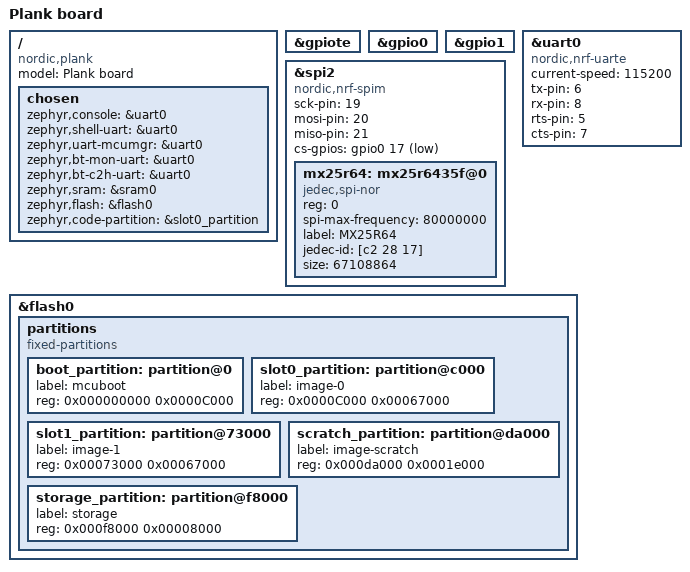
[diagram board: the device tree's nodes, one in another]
/*
 * Copyright (c) 2017 Linaro Limited
 *
 * SPDX-License-Identifier: Apache-2.0
 */

/dts-v1/;
#include <nordic/nrf52840_qiaa.dtsi>

/ {
    model = "Plank board";
    compatible = "nordic,plank";

    chosen {
        zephyr,console = &uart0;
        zephyr,shell-uart = &uart0;
        zephyr,uart-mcumgr = &uart0;
        zephyr,bt-mon-uart = &uart0;
        zephyr,bt-c2h-uart = &uart0;
        zephyr,sram = &sram0;
        zephyr,flash = &flash0;
        zephyr,code-partition = &slot0_partition;
    };
};

&gpiote {
    status = "okay";
};

&gpio0 {
    status = "okay";
};

&gpio1 {
    status = "okay";
};

&uart0 {
    compatible = "nordic,nrf-uarte";
    status = "okay";
    current-speed = <115200>;
    tx-pin = <6>;
    rx-pin = <8>;
    rts-pin = <5>;
    cts-pin = <7>;
};

&spi2 {
    compatible = "nordic,nrf-spim";
    status = "okay";
    sck-pin = <19>;
    mosi-pin = <20>;
    miso-pin = <21>;
    cs-gpios = <&gpio0 17 GPIO_ACTIVE_LOW>;
    mx25r64: mx25r6435f@0 {
        compatible = "jedec,spi-nor";
        reg = <0>;
        spi-max-frequency = <80000000>;
        label = "MX25R64";
        jedec-id = [c2 28 17];
        size = <67108864>;
    };
};

&flash0 {
    partitions {
        compatible = "fixed-partitions";
        #address-cells = <1>;
        #size-cells = <1>;

        boot_partition: partition@0 {
            label = "mcuboot";
            reg = <0x000000000 0x0000C000>;
        };
        slot0_partition: partition@c000 {
            label = "image-0";
            reg = <0x0000C000 0x00067000>;
        };
        slot1_partition: partition@73000 {
            label = "image-1";
            reg = <0x00073000 0x00067000>;
        };
        scratch_partition: partition@da000 {
            label = "image-scratch";
            reg = <0x000da000 0x0001e000>;
        };

        /*
         * The flash starting at 0x000f8000 and ending at
         * 0x000fffff is reserved for use by the application.
         */

        /*
         * Storage partition will be used by FCB/LittleFS/NVS
         * if enabled.
         */
        storage_partition: partition@f8000 {
            label = "storage";
            reg = <0x000f8000 0x00008000>;
        };
    };
};
